# ESP32C5_RADIO register map
Vendor: Espressif; Series: ESP32-C5; File version: 0.1
Registers are 32-bit, read-write, no defined reset value unless marked. A register's access mark holds for its fields unless they carry their own. Offsets are from the block's base; [hi:lo] are bit positions; {n}, {i} and the like mark numbered series; 'fields as' and 'values as' point back to an identical list.

## LP_AON_RADIO — ESP32-C5 LP_AON field the PHY's power-detector SAR initialization drives. Other fields remain absent and are preserved by every field transaction.
Base 0x600B1000
0x54 SAR_CCT — SAR control word.
  [31:29] SAR2_PWDET_CCT — Three-bit SAR2 power-detector capacitor code.

## APB_SARADC_RADIO — ESP32-C5 APB_SARADC field the PHY's power-detector initialization drives. Other fields remain absent and are preserved by every field transaction.
Base 0x6000E000
0x00 CTRL reset 0x40038240 — SAR ADC control word.
  [29] SARADC2_PWDET_DRV — Drive SAR ADC2 from the power detector.
0x58 TSENS_CTRL reset 0x18080 — Temperature-sensor control.
  [22] TSENS_PU — Power up the temperature sensor.
0x5C TSENS_CTRL2 reset 0x4002 — Temperature-sensor control 2.
  [15] TSENS_CLK_SEL — Select the temperature-sensor clock.

## PCR_RADIO — ESP32-C5 PCR fields the PHY drives: the SAR ADC and temperature-sensor clocks and one word the public header does not describe. Other fields remain absent and are preserved by every field transaction.
Base 0x60096000
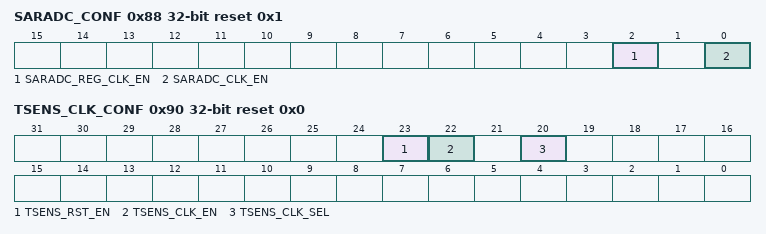
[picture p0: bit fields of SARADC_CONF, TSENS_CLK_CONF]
0x88 SARADC_CONF reset 0x1 — SAR ADC clock and reset.
  [2] SARADC_REG_CLK_EN — Enable the SAR ADC register clock.
  [0] SARADC_CLK_EN — Enable the SAR ADC clock.
0x90 TSENS_CLK_CONF reset 0x0 — Temperature-sensor clock and reset.
  [23] TSENS_RST_EN — Hold the temperature sensor in reset.
  [22] TSENS_CLK_EN — Enable the temperature-sensor clock.
  [20] TSENS_CLK_SEL — Select the temperature-sensor clock source.
0x14C WORD_014C_OPAQUE — Opaque: meaning not established. Word between PCR_SAR_CLK_DIV and PCR_BS_CONF that the public header does not describe; phy_rf_init replaces its low byte with 0x0A.
  [7:0] BITS_0_7_OPAQUE — Opaque: meaning not established. Low byte; meaning unknown.

## WIFI_MAC_AUX_TSF_CONTROL — SoftAP, NAN and broadcast-TWT TSF control words. Complete public leaves prove their addresses and exact enable/mode masks; unrelated bits and hardware transition rules remain unnamed.
Base 0x600AD860
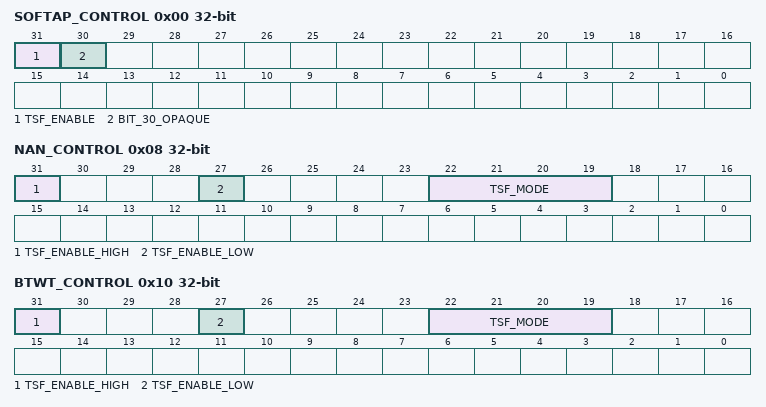
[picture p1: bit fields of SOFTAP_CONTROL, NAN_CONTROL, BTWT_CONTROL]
0x00 SOFTAP_CONTROL — Project-assigned name. Complete hal_disable_softap_tsf clears bits 31:30. Generic TSF enable/disable leaves independently identify bit 31 as the domain enable; bit 30 remains unknown.
  [31] TSF_ENABLE — Project-assigned name.
  [30] BIT_30_OPAQUE — Opaque: meaning not established.
0x08 NAN_CONTROL — Project-assigned name. Complete NAN enable/disable leaves use the same two-stage gate and mode transaction as station TSF at this distinct word.
  [31] TSF_ENABLE_HIGH — Project-assigned name.
  [27] TSF_ENABLE_LOW — Project-assigned name.
  [22:19] TSF_MODE — Project-assigned name.
0x10 BTWT_CONTROL — Project-assigned name. Complete hal_enable_sta_btwt_tsf enables or disables the broadcast-TWT TSF domain using the same gate and mode masks as station TSF.
  fields as NAN_CONTROL

## WIFI_MAC_BSSID_POLICY — Per-interface BSSID address and policy words used by scan and associated-STA receive filtering.
Base 0x600A4000
{0x0+8i} BSSID_LOW{i} (i=0..3) — Project-assigned name. BSSID bytes 0..3 for interfaces 0..3; hal_mac_set_bssid publishes a complete full-word store.
  [31:0] BYTES_0_3 — Project-assigned name.
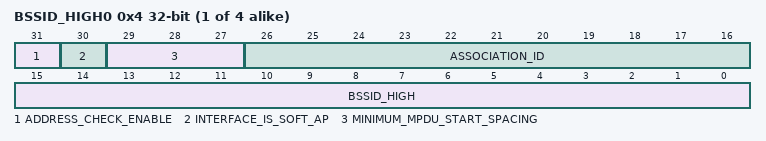
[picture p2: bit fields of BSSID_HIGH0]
{0x4+8i} BSSID_HIGH{i} (i=0..3) — Project-assigned name. Canonical high BSSID, association identity and interface policy word for interfaces 0..3. Complete dbg_read_rx_misc independently decodes every field; the HE association leaf updates the MMSS/AID fields of interface zero rather than defining a second register identity.
  [31] ADDRESS_CHECK_ENABLE — Project-assigned name. MACBSSID_EN: hal_mac_set_bssid clears this bit before changing the address and sets it after publication; the reachable associated-STA policy branch also sets it.
  [30] INTERFACE_IS_SOFT_AP — Project-assigned name. Cleared for interface zero by the associated-STA policy-five transaction.
  [29:27] MINIMUM_MPDU_START_SPACING — Project-assigned name. Three-bit MMSS value printed by dbg_read_rx_misc.
  [26:16] ASSOCIATION_ID — Project-assigned name. Eleven-bit AID printed by dbg_read_rx_misc.
  [15:0] BSSID_HIGH — Project-assigned name.
